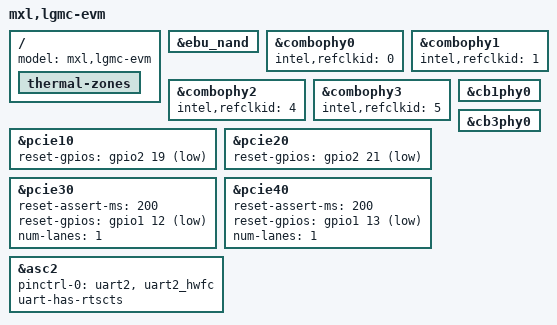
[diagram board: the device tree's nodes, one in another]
// SPDX-License-Identifier: GPL-2.0
/*
 * Copyright (C) 2024 MaxLinear, Inc.
 */

#include "octopus_640_base.dtsi"

/{
	model = "mxl,lgmc-evm";

	thermal-zones {
		/delete-node/ cpu2-thermal;
		/delete-node/ cpu3-thermal;
		/delete-node/ p34_thermal;
	};
};

&ebu_nand {
	status = "okay";
};

&combophy0 {
	intel,refclkid = <0>;
};

&combophy1 {
	intel,refclkid = <1>;
};

&combophy2 {
	intel,refclkid = <4>;
};

&combophy3 {
	intel,refclkid = <5>;
};

&cb1phy0 {
	/delete-property/ mxl,peripheral;
};

&cb3phy0 {
	/delete-property/ mxl,peripheral;
};

/* PCIe */
&pcie10 {
	reset-gpios = <&gpio2 19 GPIO_ACTIVE_LOW>; /* GPIO 83 */
};

&pcie20 {
	reset-gpios = <&gpio2 21 GPIO_ACTIVE_LOW>; /* GPIO 85 */
};

&pcie30 {
	status = "okay";
	reset-assert-ms = <200>;
	reset-gpios = <&gpio1 12 GPIO_ACTIVE_LOW>; /* GPIO 44 */
	num-lanes = <1>;
};

&pcie40 {
	status = "okay";
	reset-assert-ms = <200>;
	reset-gpios = <&gpio1 13 GPIO_ACTIVE_LOW>; /* GPIO 45 */
	num-lanes = <1>;
};

&asc2 {
	status = "okay";
	pinctrl-0 = <&uart2>, <&uart2_hwfc>;
	uart-has-rtscts;
};
